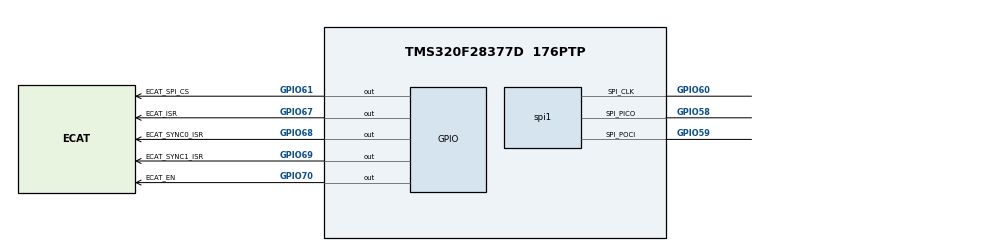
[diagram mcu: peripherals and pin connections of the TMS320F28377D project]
/**
 * These arguments were used when this file was generated. They will be automatically applied on subsequent loads
 * via the GUI or CLI. Run CLI with '--help' for additional information on how to override these arguments.
 * @cliArgs --device "F2837xD" --part "F2837xD_176PTP" --package "F2837xD_176PTP" --context "CPU1" --product "C2000WARE@6.00.01.00"
 * @v2CliArgs --device "TMS320F28377D" --package "176PTP" --context "CPU1" --product "C2000WARE@6.00.01.00"
 * @versions {"tool":"1.26.2+4477"}
 */

/**
 * Import the modules used in this configuration.
 */
const cputimer         = scripting.addModule("/driverlib/cputimer.js", {}, false);
const cputimer1        = cputimer.addInstance();
const gpio             = scripting.addModule("/driverlib/gpio.js", {}, false);
const gpio1            = gpio.addInstance();
const gpio2            = gpio.addInstance();
const gpio3            = gpio.addInstance();
const gpio4            = gpio.addInstance();
const gpio5            = gpio.addInstance();
const inputxbar        = scripting.addModule("/driverlib/inputxbar.js", {}, false);
const inputxbar1       = inputxbar.addInstance();
const inputxbar_input  = scripting.addModule("/driverlib/inputxbar_input.js", {}, false);
const inputxbar_input1 = inputxbar_input.addInstance();
const inputxbar_input2 = inputxbar_input.addInstance();
const inputxbar_input3 = inputxbar_input.addInstance();
const spi              = scripting.addModule("/driverlib/spi.js", {}, false);
const spi1             = spi.addInstance();

/**
 * Write custom configuration values to the imported modules.
 */
const divider3 = system.clockTree["EPWMCLKDIV"];
scripting.suppress("ePWM TZFRC and TZCLR events will sometimes be missed when EPWMCLKDIV is divide by 2\\. Always program EPWMCLKDIV to divide by 1 if using TZFRC or TZCLR register\\. Please refer to the F2837xD Silicon Errata for more details\\.", divider3, "EPWMCLK");

cputimer1.enableInterrupt          = true;
cputimer1.emulationMode            = "CPUTIMER_EMULATIONMODE_RUNFREE";
cputimer1.$name                    = "myCPUTIMER1";
cputimer1.registerInterrupts       = true;
cputimer1.cputimerBase             = "CPUTIMER2_BASE";
cputimer1.timerPeriod              = 4294967295;
cputimer1.timerPrescaler           = 199;
cputimer1.timerInt.enableInterrupt = true;

gpio1.$name           = "ECAT_SPI_CS";
gpio1.direction       = "GPIO_DIR_MODE_OUT";
gpio1.gpioPin.$assign = "GPIO61";

gpio2.useInterrupt               = true;
gpio2.$name                      = "ECAT_ISR";
gpio2.gpioPin.$assign            = "GPIO67";
gpio2.xint.enableInt             = true;
gpio2.xint.registerInterrupts    = true;
gpio2.xint.xInt.enableInterrupt  = true;
gpio2.xint.xInt.interruptHandler = "ECAT_Lan9252IrqIsr";

gpio3.$name                      = "ECAT_SYNC0_ISR";
gpio3.useInterrupt               = true;
gpio3.gpioPin.$assign            = "GPIO68";
gpio3.xint.xintNum               = "GPIO_INT_XINT2";
gpio3.xint.enableInt             = true;
gpio3.xint.registerInterrupts    = true;
gpio3.xint.xInt.interruptHandler = "ECAT_Sync0Isr";
gpio3.xint.xInt.enableInterrupt  = true;

gpio4.$name                      = "ECAT_SYNC1_ISR";
gpio4.useInterrupt               = true;
gpio4.gpioPin.$assign            = "GPIO69";
gpio4.xint.xintNum               = "GPIO_INT_XINT3";
gpio4.xint.enableInt             = true;
gpio4.xint.registerInterrupts    = true;
gpio4.xint.xInt.interruptHandler = "ECAT_Sync1Isr";
gpio4.xint.xInt.enableInterrupt  = true;

gpio5.$name           = "ECAT_EN";
gpio5.direction       = "GPIO_DIR_MODE_OUT";
gpio5.gpioPin.$assign = "GPIO70";

inputxbar1.$name = "myINPUTXBAR";

inputxbar_input1.$name         = "myINPUTXBARINPUT0";
gpio2.xint.inputxbar           = inputxbar_input1;
inputxbar_input1.inputxbarGpio = "GPIO67";

inputxbar_input2.$name         = "myINPUTXBARINPUT1";
gpio3.xint.inputxbar           = inputxbar_input2;
inputxbar_input2.inputxbarGpio = "GPIO68";

inputxbar_input3.$name         = "myINPUTXBARINPUT2";
gpio4.xint.inputxbar           = inputxbar_input3;
inputxbar_input3.inputxbarGpio = "GPIO69";

spi1.$name                   = "mySPI0";
spi1.transferProtocol        = "SPI_PROT_POL1PHA0";
spi1.dataWidth               = "8";
spi1.useCase                 = "CUSTOM";
spi1.useInterfacePins        = ["SPICLK@","SPISIMO@","SPISOMI@"];
spi1.mode                    = "SPI_MODE_CONTROLLER";
spi1.useInterrupts           = false;
spi1.spi.$assign             = "SPIA";
spi1.spi.spi_picoPin.$assign = "GPIO58";
spi1.spi.spi_pociPin.$assign = "GPIO59";
spi1.spi.spi_clkPin.$assign  = "GPIO60";
spi1.clkQual.$name           = "myGPIOQUAL2";
spi1.picoQual.$name          = "myGPIOQUAL0";
spi1.pociQual.$name          = "myGPIOQUAL1";
